VERSION ""

NS_ :

BS_:

BU_: VESC

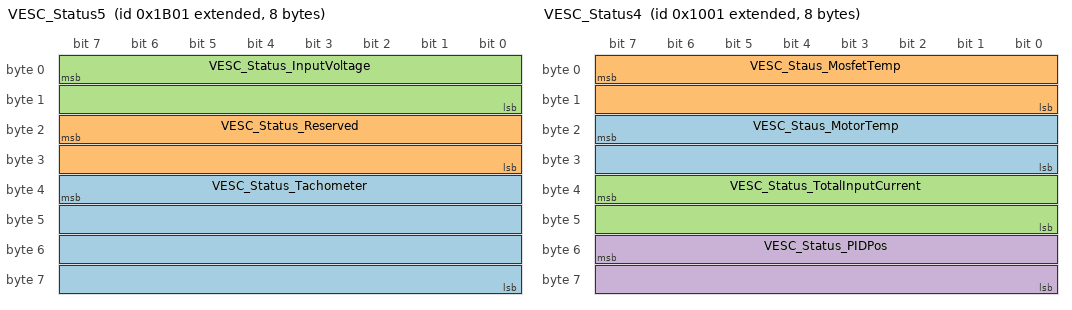
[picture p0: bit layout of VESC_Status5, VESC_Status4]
BO_ 2147490561 VESC_Status5: 8 VESC
 SG_ VESC_Status_Tachometer : 39|32@0- (1,0) [0|0] "RPM" Vector__XXX
 SG_ VESC_Status_Reserved : 23|16@0- (1,0) [0|0] "" Vector__XXX
 SG_ VESC_Status_InputVoltage : 7|16@0- (0.1,0) [0|0] "" Vector__XXX

BO_ 2147487745 VESC_Status4: 8 VESC
 SG_ VESC_Staus_MotorTemp : 23|16@0- (0.1,0) [-3276.8|3276.7] "°C" Vector__XXX
 SG_ VESC_Staus_MosfetTemp : 7|16@0- (0.1,0) [-3276.8|3276.7] "°C" Vector__XXX
 SG_ VESC_Status_TotalInputCurrent : 39|16@0- (0.1,0) [-3276.8|3276.7] "A" Vector__XXX
 SG_ VESC_Status_PIDPos : 55|16@0- (0.02,0) [-655.36|655.34] "" Vector__XXX

BO_ 2147487489 VESC_Status3: 8 VESC
 SG_ VESC_Status_WattHoursCharged : 39|32@0- (1E-005,0) [-21474.83648|21474.83647] "Wh" Vector__XXX
 SG_ VESC_Status_WattHours : 7|32@0- (1E-005,0) [-21474.83648|21474.83647] "Wh" Vector__XXX

BO_ 2147487233 VESC_Status2: 8 VESC
 SG_ VESC_Status_AmpHoursCharged : 39|32@0- (1E-005,0) [-21474.83648|21474.83647] "Ah" Vector__XXX
 SG_ VESC_Status_AmpHours : 7|32@0- (1E-005,0) [-21474.83648|21474.83647] "Ah" Vector__XXX

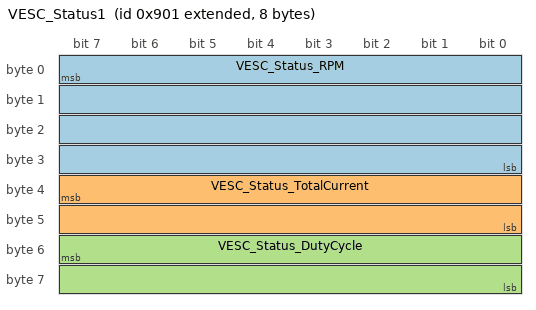
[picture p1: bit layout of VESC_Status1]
BO_ 2147485953 VESC_Status1: 8 VESC
 SG_ VESC_Status_RPM : 7|32@0- (1,0) [-2147483648|2147483647] "RPM" Vector__XXX
 SG_ VESC_Status_TotalCurrent : 39|16@0- (0.1,0) [-3276.8|3276.7] "A" Vector__XXX
 SG_ VESC_Status_DutyCycle : 55|16@0- (0.1,0) [-100|100] "%" Vector__XXX

BA_DEF_ SG_  "GenSigSendType" ENUM  "Cyclic","OnWrite","OnWriteWithRepetition","OnChange","OnChangeWithRepetition","IfActive","IfActiveWithRepetition","NoSigSendType","NotUsed","NotUsed","NotUsed","NotUsed","NotUsed";
BA_DEF_ BO_  "GenMsgILSupport" ENUM  "No","Yes";
BA_DEF_ BO_  "GenMsgSendType2" ENUM  "Zyklisch","Ereignisgesteuert","dummy","Auf Anfrage";
BA_DEF_ BO_  "GenMsgFastOnStart" INT 10 500;
BA_DEF_ BO_  "GenMsgCycleTimeActive" INT 1 100;
BA_DEF_ BO_  "VFrameFormat" ENUM  "StandardCAN","ExtendedCAN","reserved","reserved","reserved","reserved","reserved","reserved","reserved","reserved","reserved","reserved","reserved","reserved","StandardCAN_FD","ExtendedCAN_FD";
BA_DEF_ BO_  "GenMsgSendType" ENUM  "Cyclic","NotUsed","NotUsed","NotUsed","NotUsed","NotUsed","NotUsed","IfActive","NoMsgSendType","NotUsed","vector_leerstring";
BA_DEF_  "BusType" STRING ;
BA_DEF_DEF_  "GenSigSendType" "Cyclic";
BA_DEF_DEF_  "GenMsgILSupport" "Yes";
BA_DEF_DEF_  "GenMsgSendType2" "Zyklisch";
BA_DEF_DEF_  "GenMsgFastOnStart" 10;
BA_DEF_DEF_  "GenMsgCycleTimeActive" 10;
BA_DEF_DEF_  "VFrameFormat" "ExtendedCAN_FD";
BA_DEF_DEF_  "GenMsgSendType" "NoMsgSendType";
BA_DEF_DEF_  "BusType" "CAN";
BA_ "VFrameFormat" BO_ 2147490561 1;
BA_ "VFrameFormat" BO_ 2147487745 1;
BA_ "VFrameFormat" BO_ 2147487489 1;
BA_ "VFrameFormat" BO_ 2147487233 1;
BA_ "VFrameFormat" BO_ 2147485953 1;
